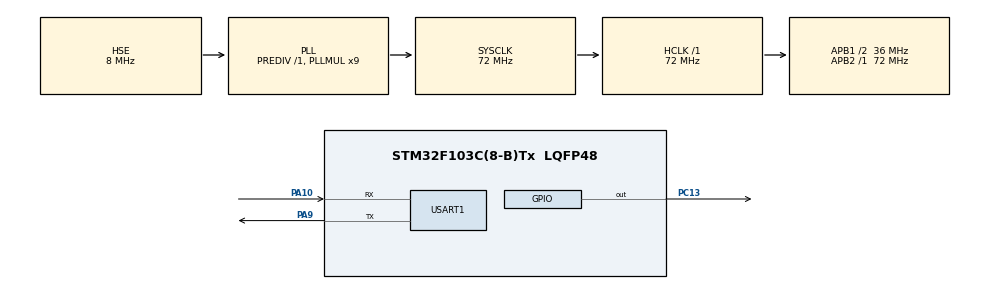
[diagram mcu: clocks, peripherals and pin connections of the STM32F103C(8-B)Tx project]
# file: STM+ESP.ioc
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Mcu.Family=STM32F1
Mcu.Name=STM32F103C(8-B)Tx
Mcu.Package=LQFP48
NVIC.PriorityGroup=NVIC_PRIORITYGROUP_4
NVIC.USART1_IRQn=true\:0\:0\:false\:false\:true\:true\:true
PA10.Mode=Asynchronous
PA10.Signal=USART1_RX
PA13.Mode=Serial_Wire
PA13.Signal=SYS_JTMS-SWDIO
PA14.Mode=Serial_Wire
PA14.Signal=SYS_JTCK-SWCLK
PA9.Mode=Asynchronous
PA9.Signal=USART1_TX
PC13-TAMPER-RTC.Signal=GPIO_Output
PC14-OSC32_IN.Mode=LSE-External-Oscillator
PC14-OSC32_IN.Signal=RCC_OSC32_IN
PC15-OSC32_OUT.Mode=LSE-External-Oscillator
PC15-OSC32_OUT.Signal=RCC_OSC32_OUT
PD0-OSC_IN.Mode=HSE-External-Oscillator
PD0-OSC_IN.Signal=RCC_OSC_IN
PD1-OSC_OUT.Mode=HSE-External-Oscillator
PD1-OSC_OUT.Signal=RCC_OSC_OUT
ProjectManager.HeapSize=0x200
ProjectManager.StackSize=0x400
ProjectManager.TargetToolchain=MDK-ARM V5.27
RCC.AHBFreq_Value=72000000
RCC.APB1CLKDivider=RCC_HCLK_DIV2
RCC.APB1Freq_Value=36000000
RCC.APB1TimFreq_Value=72000000
RCC.APB2Freq_Value=72000000
RCC.APB2TimFreq_Value=72000000
RCC.HCLKFreq_Value=72000000
RCC.PLLMUL=RCC_PLL_MUL9
RCC.PLLSourceVirtual=RCC_PLLSOURCE_HSE
RCC.SYSCLKFreq_VALUE=72000000
RCC.SYSCLKSource=RCC_SYSCLKSOURCE_PLLCLK
RCC.USBFreq_Value=72000000
USART1.VirtualMode=VM_ASYNC
board=custom

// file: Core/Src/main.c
/* USER CODE BEGIN Header */
/**
  ******************************************************************************
  * @file           : main.c
  * @brief          : Main program body
  ******************************************************************************
  * @attention
  *
  * <h2><center>&copy; Copyright (c) 2020 STMicroelectronics.
  * All rights reserved.</center></h2>
  *
  * This software component is licensed by ST under BSD 3-Clause license,
  * the "License"; You may not use this file except in compliance with the
  * License. You may obtain a copy of the License at:
  *                        opensource.org/licenses/BSD-3-Clause
  *
  ******************************************************************************
  */
/* USER CODE END Header */
#include "main.h"

/* USER CODE BEGIN Includes */

#include "string.h"

/* USER CODE END Includes */

UART_HandleTypeDef huart1;

/* USER CODE BEGIN PV */

	uint8_t buff[31];

	uint8_t buff0[31];

	//uint8_t tbuff[31] = { 'f',};

	char* chbuff;

	char* nbuff = "+MQTTSUBRECV:0,\"esp-test\",1,1\r\n";

	char* fbuff = "+MQTTSUBRECV:0,\"esp-test\",1,0\r\n";

	int k;
	int i;

/* USER CODE END PV */

void SystemClock_Config(void);
static void MX_GPIO_Init(void);
static void MX_USART1_UART_Init(void);

/* USER CODE BEGIN 0 */

	void Zero (void)
	{

		for (i=0; i<31; i++){
						buff0[i] = 0;
			}
		i=0;
	}

	//main

	void LED_ON_OFF (void)
	{

	chbuff = (char*)buff;

		if( strcmp (chbuff, nbuff) == 0 ) {

			HAL_GPIO_WritePin(GPIOC, GPIO_PIN_13, GPIO_PIN_RESET);

			if (HAL_GPIO_ReadPin (GPIOC, GPIO_PIN_13) == GPIO_PIN_RESET) {

			HAL_UART_Transmit(&huart1, (uint8_t*)"AT+MQTTPUB=0,\"esp-callback\",\"on\",1,0\r\n", 38, 1000);

			} else {

				HAL_UART_Transmit(&huart1, (uint8_t*)"AT+MQTTPUB=0,\"esp-callback\",\"off\",1,0\r\n", 39, 1000);

			}

			HAL_Delay(300);

			for (i=0; i<31; i++){
						buff[i] = 0;
						}
			i=0;

		} else if( strcmp (chbuff, fbuff) == 0 ) {

			HAL_GPIO_WritePin(GPIOC, GPIO_PIN_13, GPIO_PIN_SET);

			if (HAL_GPIO_ReadPin (GPIOC, GPIO_PIN_13) == GPIO_PIN_SET) {

			HAL_UART_Transmit(&huart1, (uint8_t*)"AT+MQTTPUB=0,\"esp-callback\",\"off\",1,0\r\n", 39, 1000);

			} else {

				HAL_UART_Transmit(&huart1, (uint8_t*)"AT+MQTTPUB=0,\"esp-callback\",\"on\",1,0\r\n", 38, 1000);

			}

			HAL_Delay(300);

			for (i=0; i<31; i++){
						buff[i] = 0;
			}
			i=0;

		}

	//	UART_ClearITPendingBit(&huart1, UART_IT_RXNE)

	}

/* USER CODE END 0 */

int main(void)
{
  /* USER CODE BEGIN 1 */

	Zero();

  /* USER CODE END 1 */

  /* MCU Configuration--------------------------------------------------------*/

  /* Reset of all peripherals, Initializes the Flash interface and the Systick. */
  HAL_Init();

  /* Configure the system clock */
  SystemClock_Config();

  /* Initialize all configured peripherals */
  MX_GPIO_Init();
  MX_USART1_UART_Init();
  /* USER CODE BEGIN 2 */

	// HAL_UART_Transmit(&huart1, (uint8_t*)"AT+RST\r\n", 8, 1000);
	HAL_Delay(3000);
	HAL_UART_Transmit(&huart1, (uint8_t*)"AT+CWMODE=1\r\n", 13, 1000);
	HAL_Delay(1000);
	HAL_UART_Transmit(&huart1, (uint8_t*)"AT+SLEEP=0\r\n", 12, 1000);
	HAL_Delay(1000);
	HAL_UART_Transmit(&huart1, (uint8_t*)"AT+CIPMUX=1\r\n", 13, 1000);
	HAL_Delay(1000);
	HAL_UART_Transmit(&huart1, (uint8_t*)"AT+CIPSNTPCFG=1,3,\"0.ua.pool.ntp.org\"\r\n", 39, 1000);
	HAL_Delay(1000);
	HAL_UART_Transmit(&huart1, (uint8_t*)"AT+MQTTUSERCFG=0,1,\"ESP-32_Test\",\"\",\"\",0,0,\"\"\r\n", 47, 1000);
	HAL_Delay(1000);
	HAL_UART_Transmit(&huart1, (uint8_t*)"AT+MQTTCONN=0,\"broker.hivemq.com\",1883,1\r\n", 42, 1000);
	HAL_Delay(1000);
	HAL_UART_Transmit(&huart1, (uint8_t*)"AT+MQTTSUB=0,\"esp-test\",1\r\n", 27, 1000);
	HAL_Delay(1000);
	//HAL_UART_Transmit(&huart1, (uint8_t*)"AT+MQTTSUB=0,\"esp-callback\",1\r\n", 31, 1000);
	//HAL_Delay(1000);
	HAL_UART_Transmit(&huart1, (uint8_t*)"AT+MQTTPUB=0,\"esp-callback\",\"I am On\",1,0\r\n", 43, 1000);
	HAL_Delay(1000);

	HAL_GPIO_WritePin(GPIOC, GPIO_PIN_13, GPIO_PIN_SET);

  /* USER CODE END 2 */

  /* Infinite loop */
  /* USER CODE BEGIN WHILE */
  while (1)
  {

//		HAL_GPIO_TogglePin(GPIOC, GPIO_PIN_13);
//		HAL_Delay(1000);

//		HAL_GPIO_WritePin(GPIOC, GPIO_PIN_13, GPIO_PIN_RESET);
//		HAL_Delay(1000);
//		HAL_GPIO_WritePin(GPIOC, GPIO_PIN_13, GPIO_PIN_SET);
//		HAL_Delay(1000);

		HAL_UART_Receive_IT(&huart1, buff, 31);

	//	if (UART_FLAG_RXNE != 0) {

		LED_ON_OFF();

	//	}

    /* USER CODE END WHILE */

  }
}

void SystemClock_Config(void)
{
  RCC_OscInitTypeDef RCC_OscInitStruct = {0};
  RCC_ClkInitTypeDef RCC_ClkInitStruct = {0};

  /** Initializes the RCC Oscillators according to the specified parameters
  * in the RCC_OscInitTypeDef structure.
  */
  RCC_OscInitStruct.OscillatorType = RCC_OSCILLATORTYPE_HSE;
  RCC_OscInitStruct.HSEState = RCC_HSE_ON;
  RCC_OscInitStruct.HSEPredivValue = RCC_HSE_PREDIV_DIV1;
  RCC_OscInitStruct.HSIState = RCC_HSI_ON;
  RCC_OscInitStruct.PLL.PLLState = RCC_PLL_ON;
  RCC_OscInitStruct.PLL.PLLSource = RCC_PLLSOURCE_HSE;
  RCC_OscInitStruct.PLL.PLLMUL = RCC_PLL_MUL9;
  if (HAL_RCC_OscConfig(&RCC_OscInitStruct) != HAL_OK)
  {
    Error_Handler();
  }
  /** Initializes the CPU, AHB and APB buses clocks
  */
  RCC_ClkInitStruct.ClockType = RCC_CLOCKTYPE_HCLK|RCC_CLOCKTYPE_SYSCLK
                              |RCC_CLOCKTYPE_PCLK1|RCC_CLOCKTYPE_PCLK2;
  RCC_ClkInitStruct.SYSCLKSource = RCC_SYSCLKSOURCE_PLLCLK;
  RCC_ClkInitStruct.AHBCLKDivider = RCC_SYSCLK_DIV1;
  RCC_ClkInitStruct.APB1CLKDivider = RCC_HCLK_DIV2;
  RCC_ClkInitStruct.APB2CLKDivider = RCC_HCLK_DIV1;

  if (HAL_RCC_ClockConfig(&RCC_ClkInitStruct, FLASH_LATENCY_2) != HAL_OK)
  {
    Error_Handler();
  }
}

static void MX_USART1_UART_Init(void)
{

  huart1.Instance = USART1;
  huart1.Init.BaudRate = 115200;
  huart1.Init.WordLength = UART_WORDLENGTH_8B;
  huart1.Init.StopBits = UART_STOPBITS_1;
  huart1.Init.Parity = UART_PARITY_NONE;
  huart1.Init.Mode = UART_MODE_TX_RX;
  huart1.Init.HwFlowCtl = UART_HWCONTROL_NONE;
  huart1.Init.OverSampling = UART_OVERSAMPLING_16;
  if (HAL_UART_Init(&huart1) != HAL_OK)
  {
    Error_Handler();
  }

}

static void MX_GPIO_Init(void)
{
  GPIO_InitTypeDef GPIO_InitStruct = {0};

  /* GPIO Ports Clock Enable */
  __HAL_RCC_GPIOC_CLK_ENABLE();
  __HAL_RCC_GPIOD_CLK_ENABLE();
  __HAL_RCC_GPIOA_CLK_ENABLE();

  /*Configure GPIO pin Output Level */
  HAL_GPIO_WritePin(GPIOC, GPIO_PIN_13, GPIO_PIN_RESET);

  /*Configure GPIO pin : PC13 */
  GPIO_InitStruct.Pin = GPIO_PIN_13;
  GPIO_InitStruct.Mode = GPIO_MODE_OUTPUT_PP;
  GPIO_InitStruct.Pull = GPIO_NOPULL;
  GPIO_InitStruct.Speed = GPIO_SPEED_FREQ_LOW;
  HAL_GPIO_Init(GPIOC, &GPIO_InitStruct);

}

void Error_Handler(void)
{
}

/************************ (C) COPYRIGHT STMicroelectronics *****END OF FILE****/
